# RA2A1 register map
Vendor: Renesas Electronics Corporation; Series: RA2; File version: 1.1
CPU: other r1p0, little endian, MPU, no FPU, VTOR, 2 interrupt priority bits
Registers are 8-bit, read-write, reset 0x0 unless marked. A register's access mark holds for its fields unless they carry their own. Offsets are from the block's base; [hi:lo] are bit positions; {n}, {i} and the like mark numbered series; 'fields as' and 'values as' point back to an identical list.

## USBFS — USB 2.0 FS Module
Base 0x40090000
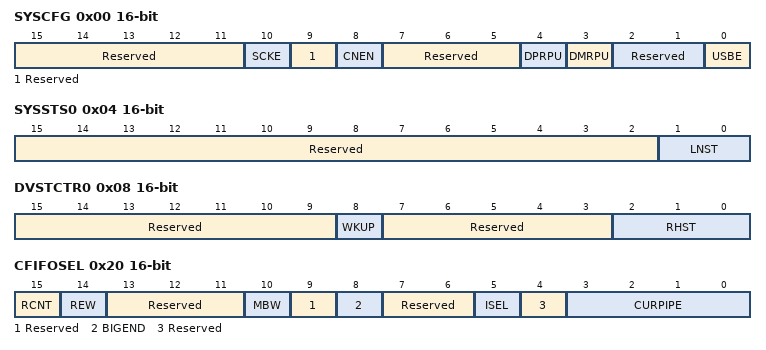
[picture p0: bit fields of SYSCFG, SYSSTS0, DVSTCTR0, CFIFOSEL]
0x00 SYSCFG 16-bit — System Configuration Control Register
  [15:11] Reserved — These bits are read as 00000. The write value should be 00000.
  [10] SCKE — USB Clock Enable
    0=Stops supplying the clock signal to the USB; 1=Enables supplying the clock signal to the USB
  [9] Reserved — This bit is read as 0. The write value should be 0.
  [8] CNEN — CNEN Single End Receiver Enable
    0=Single end receiver operation is disabled; 1=Single end receiver operation is enabled
  [7:5] Reserved — These bits are read as 000. The write value should be 000.
  [4] DPRPU — D+ Line Resistor Control
    0=Pulling up the line is disabled; 1=Pulling up the line is enabled
  [3] DMRPU — D- Line Resistor Control
    values as DPRPU
  [2:1] Reserved — These bits are read as 00. The write value should be 00.
  [0] USBE — USB Operation Enable
    0=USB operation is disabled; 1=USB operation is enabled
0x04 SYSSTS0 16-bit ro — System Configuration Status Register 0
  [15:2] Reserved — These bits are read as 00000000000000.
  [1:0] LNST — USB Data Line Status Monitor
    0=SE0; 1=J-State; 2=K-State; 3=SE1
0x08 DVSTCTR0 16-bit — Device State Control Register 0
  [15:9] Reserved — These bits are read as 0000000. The write value should be 0000000.
  [8] WKUP — Wakeup Detection Enable
    0=Remote wakeup signal is not output; 1=Remote wakeup signal is output
  [7:3] Reserved — These bits are read as 00000. The write value should be 00000.
  [2:0] RHST ro — USB Bus Reset Status
    0=Communication speed not determined; 1=USB bus reset in progress or low-speed connection; 2=USB bus reset in progress or full-speed connection; other=others (Setting prohibited)
0x14 CFIFO 16-bit — CFIFO Port Register
  [15:0] FIFOPORT — FIFO PortRead receive data from the FIFO buffer or write transmit data to the FIFO buffer by accessing these bits.
0x14 CFIFOL (alternate view of CFIFO) — CFIFO Port Register L
0x20 CFIFOSEL 16-bit — CFIFO Port Select Register
  [15] RCNT — Read Count Mode
    0=The DTLN[8:0] bits (CFIFOCRT.DTLN[8:0], D0FIFOCRT.DTLN[8:0], D1FIFOCRT.DTLN[8:0]) are cleared when all of the receive data has been read from the CFIFO.(In double buffer mode, the DTLN[8:0] bit value is cleared when all the data has been read from only a single plane.); 1=The DTLN[8:0] bits are decremented each time the receive data is read from the CFIFO
  [14] REW wo — Buffer Pointer Rewind
    0=The buffer pointer is not rewound; 1=The buffer pointer is rewound
  [13:11] Reserved — These bits are read as 000. The write value should be 000.
  [10] MBW — CFIFO Port Access Bit Width
    0=8-bit width; 1=16-bit width
  [9] Reserved — This bit is read as 0. The write value should be 0.
  [8] BIGEND — CFIFO Port Endian Control
    0=Little endian; 1=Big endian
  [7:6] Reserved — These bits are read as 00. The write value should be 00.
  [5] ISEL — CFIFO Port Access Direction When DCP is Selected
    0=Reading from the buffer memory is selected; 1=Writing to the buffer memory is selected
  [4] Reserved — This bit is read as 0. The write value should be 0.
  [3:0] CURPIPE — CFIFO Port Access Pipe Specification
    0=DCP(Defaultcontrolpipe); {v}=Pipe{v} (v=1..9); other=others (Setting prohibited)
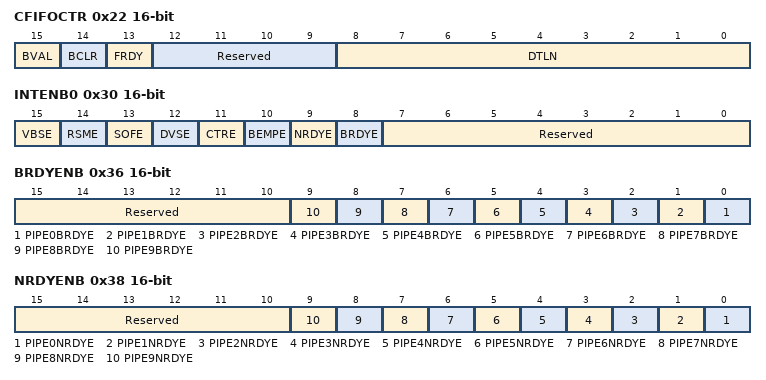
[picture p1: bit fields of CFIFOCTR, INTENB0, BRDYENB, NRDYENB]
0x22 CFIFOCTR 16-bit — CFIFO Port Control Register
  [15] BVAL — Buffer Memory Valid Flag
    0=Invalid; 1=Writing ended
  [14] BCLR wo — CPU Buffer Clear
    0=Invalid; 1=Clears the buffer memory on the CPU side
  [13] FRDY ro — FIFO Port Ready
    0=FIFO port access is disabled; 1=FIFO port access is enabled
  [12:9] Reserved — These bits are read as 0000. The write value should be 0000.
  [8:0] DTLN ro — Receive Data LengthIndicates the length of the receive data.
0x30 INTENB0 16-bit — Interrupt Enable Register 0
  [15] VBSE — VBUS Interrupt Enable
    0=Interrupt output disabled; 1=Interrupt output enabled
  [14] RSME — Resume Interrupt Enable
    0=Interrupt output disabled; 1=Interrupt output enabled
  [13] SOFE — Frame Number Update Interrupt Enable
    0=Interrupt output disabled; 1=Interrupt output enabled
  [12] DVSE — Device State Transition Interrupt Enable
    0=Interrupt output disabled; 1=Interrupt output enabled
  [11] CTRE — Control Transfer Stage Transition Interrupt Enable
    0=Interrupt output disabled; 1=Interrupt output enabled
  [10] BEMPE — Buffer Empty Interrupt Enable
    0=Interrupt output disabled; 1=Interrupt output enabled
  [9] NRDYE — Buffer Not Ready Response Interrupt Enable
    0=Interrupt output disabled; 1=Interrupt output enabled
  [8] BRDYE — Buffer Ready Interrupt Enable
    0=Interrupt output disabled; 1=Interrupt output enabled
  [7:0] Reserved — These bits are read as 00000000. The write value should be 00000000.
0x36 BRDYENB 16-bit — BRDY Interrupt Enable Register
  [15:10] Reserved — These bits are read as 000000. The write value should be 000000.
  [n] PIPE{n}BRDYE (n=0..9) — BRDY Interrupt Enable for PIPE{n}
    0=Interrupt output disabled; 1=Interrupt output enabled
0x38 NRDYENB 16-bit — NRDY Interrupt Enable Register
  [15:10] Reserved — These bits are read as 000000. The write value should be 000000.
  [n] PIPE{n}NRDYE (n=0..9) — NRDY Interrupt Enable for PIPE{n}
    0=Interrupt output disabled; 1=Interrupt output enabled
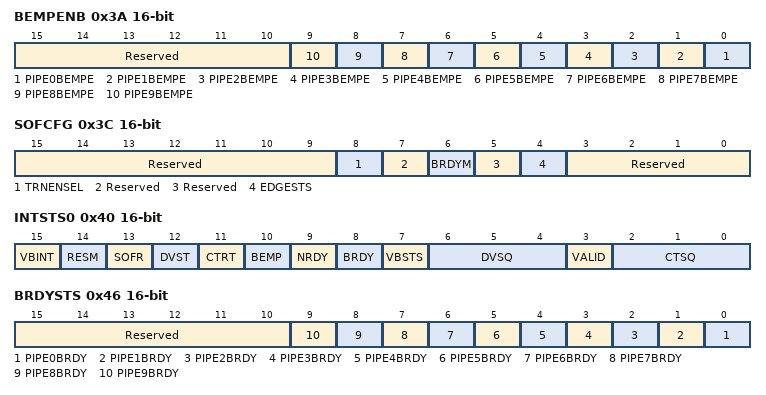
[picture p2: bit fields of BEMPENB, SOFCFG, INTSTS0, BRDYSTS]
0x3A BEMPENB 16-bit — BEMP Interrupt Enable Register
  [15:10] Reserved — These bits are read as 000000. The write value should be 000000.
  [n] PIPE{n}BEMPE (n=0..9) — BEMP Interrupt Enable for PIPE{n}
    0=Interrupt output disabled; 1=Interrupt output enabled
0x3C SOFCFG 16-bit — SOF Output Configuration Register
  [15:9] Reserved — These bits are read as 0000000. The write value should be 0000000.
  [8] TRNENSEL — Transaction-Enabled Time Select
    0=For non-low-speed communication; 1=For low-speed communication
  [7] Reserved — This bit is read as 0. The write value should be 0.
  [6] BRDYM — BRDY Interrupt Status Clear Timing
    0=Software clears the status; 1=The USB clears the status when data has been read from the FIFO buffer or data has been written to the FIFO buffer
  [5] Reserved — This bit is read as 0. The write value should be 0.
  [4] EDGESTS ro — Edge Interrupt Output Status Monitor
    0=before stopping the clock supply to the USB module; 1=the edge interrupt output signal is in the middle of the edge processing
  [3:0] Reserved — These bits are read as 0000. The write value should be 0000.
0x40 INTSTS0 16-bit (reset mask 0xFF7F) — Interrupt Status Register 0
  [15] VBINT write-0-clears read-modifies — VBUS Interrupt Status
    0=VBUS interrupts are not generated; 1=VBUS interrupts are generated
  [14] RESM write-0-clears read-modifies — Resume Interrupt Status
    0=Resume interrupts are not generated; 1=Resume interrupts are generated
  [13] SOFR write-0-clears read-modifies — Frame Number Refresh Interrupt Status
    0=SOF interrupts are not generated; 1=SOF interrupts are generated
  [12] DVST write-0-clears read-modifies — Device State Transition Interrupt Status
    0=Device state transition interrupts are not generated; 1=Device state transition interrupts are generated
  [11] CTRT write-0-clears read-modifies — Control Transfer Stage Transition Interrupt Status
    0=Control transfer stage transition interrupts are not generated; 1=Control transfer stage transition interrupts are generated
  [10] BEMP ro — Buffer Empty Interrupt Status
    0=BEMP interrupts are not generated; 1=BEMP interrupts are generated
  [9] NRDY ro — Buffer Not Ready Interrupt Status
    0=NRDY interrupts are not generated; 1=NRDY interrupts are generated
  [8] BRDY ro — Buffer Ready Interrupt Status
    0=BRDY interrupts are not generated; 1=BRDY interrupts are generated
  [7] VBSTS ro — VBUS Input Status
    0=USB0_VBUS pin is low; 1=USB0_VBUS pin is high
  [6:4] DVSQ ro — Device State
    0=Powered state; 1=Default state; 2=Address state; 3=Configured state; other=others (Suspended state)
  [3] VALID — USB Request Reception
    0=Setup packet is not received; 1=Setup packet is received
  [2:0] CTSQ ro — Control Transfer Stage
    0=Idle or setup stage; 1=Control read data stage; 2=Control read status stage; 3=Control write data stage; 4=Control write status stage; 5=Control write(nodata) status stage; 6=Control transfer sequence error; other=others (Setting prohibited)
0x46 BRDYSTS 16-bit — BRDY Interrupt Status Register
  [15:10] Reserved — These bits are read as 000000. The write value should be 000000.
  [n] PIPE{n}BRDY write-0-clears read-modifies (n=0..9) — BRDY Interrupt Status for PIPE{n}
    0=Interrupts are not generated; 1=Interrupts are generated
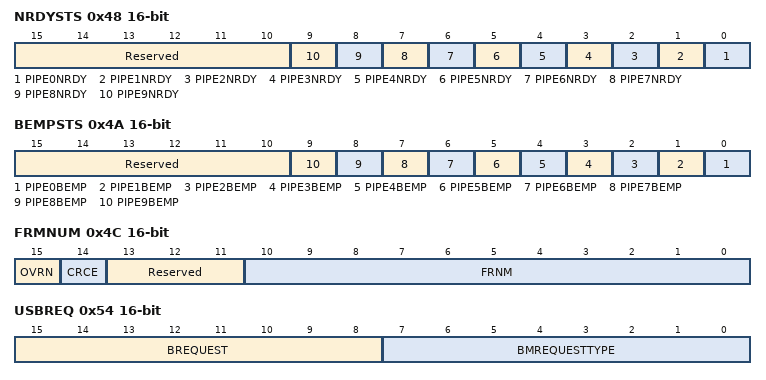
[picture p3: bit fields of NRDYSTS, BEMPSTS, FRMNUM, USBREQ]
0x48 NRDYSTS 16-bit — NRDY Interrupt Status Register
  [15:10] Reserved — These bits are read as 000000. The write value should be 000000.
  [n] PIPE{n}NRDY write-0-clears read-modifies (n=0..9) — NRDY Interrupt Status for PIPE{n}
    0=Interrupts are not generated; 1=Interrupts are generated
0x4A BEMPSTS 16-bit — BEMP Interrupt Status Register
  [15:10] Reserved — These bits are read as 000000. The write value should be 000000.
  [n] PIPE{n}BEMP write-0-clears read-modifies (n=0..9) — BEMP Interrupt Status for PIPE{n}
    0=Interrupts are not generated; 1=Interrupts are generated
0x4C FRMNUM 16-bit — Frame Number Register
  [15] OVRN — Overrun/Underrun Detection Status
    0=No error; 1=An error occurred
  [14] CRCE — Receive Data Error
    0=No error; 1=An error occurred
  [13:11] Reserved — These bits are read as 000. The write value should be 000.
  [10:0] FRNM ro — Frame NumberLatest frame number
0x54 USBREQ 16-bit ro — USB Request Type Register
  [15:8] BREQUEST — RequestThese bits store the USB request bRequest value.
  [7:0] BMREQUESTTYPE — Request TypeThese bits store the USB request bmRequestType value.
0x56 USBVAL 16-bit ro — USB Request Value Register
  [15:0] WVALUE — ValueThese bits store the USB request wValue value.
0x58 USBINDX 16-bit ro — USB Request Index Register
  [15:0] WINDEX — IndexThese bits store the USB request wIndex value.
0x5A USBLENG 16-bit ro — USB Request Length Register
  [15:0] WLENGTUH — LengthThese bits store the USB request wLength value.
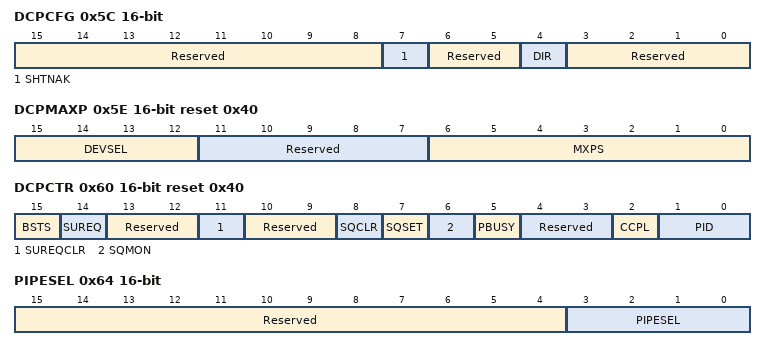
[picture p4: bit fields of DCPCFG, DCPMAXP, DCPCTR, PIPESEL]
0x5C DCPCFG 16-bit — DCP Configuration Register
  [15:8] Reserved — These bits are read as 00000000. The write value should be 00000000.
  [7] SHTNAK — Pipe Disabled at End of Transfer
    0=Pipe continued at the end of transfer; 1=Pipe disabled at the end of transfer
  [6:5] Reserved — These bits are read as 00. The write value should be 00.
  [4] DIR — Transfer Direction
    0=Data receiving direction; 1=Data transmitting direction
  [3:0] Reserved — These bits are read as 0000. The write value should be 0000.
0x5E DCPMAXP 16-bit reset 0x40 — DCP Maximum Packet Size Register
  [15:12] DEVSEL — Device Select
    0=Address 0000; 1=Address 0001; 2=Address 0010; 3=Address 0011; 4=Address 0100; 5=Address 0101; other=others (Settings prohibited.)
  [11:7] Reserved — These bits are read as 00000. The write value should be 00000.
  [6:0] MXPS — Maximum Packet SizeThese bits set the maximum amount of data (maximum packet size) in payloads for the DCP.
    8=8bytes; 16=16bytes; 24=24bytes; 32=32bytes; 40=40bytes; 48=48bytes; 56=56bytes; 64=64bytes; 72=72bytes; 80=80bytes; 88=88bytes; 96=96bytes; 104=104bytes; 112=112bytes; 120=120bytes; other=others (Setting prohibited)
0x60 DCPCTR 16-bit reset 0x40 — DCP Control Register
  [15] BSTS ro — Buffer Status
    0=Buffer access is disabled; 1=Buffer access is enabled
  [14] SUREQ — Setup Token Transmission
    0=Invalid; 1=Transmits the setup packet
  [13:12] Reserved — These bits are read as 00. The write value should be 00.
  [11] SUREQCLR — SUREQ Bit Clear
    0=Invalid; 1=Clears the SUREQ bit to 0
  [10:9] Reserved — These bits are read as 00. The write value should be 00.
  [8] SQCLR wo — Sequence Toggle Bit Clear
    0=Invalid; 1=Specifies DATA0
  [7] SQSET wo — Sequence Toggle Bit Set
    0=Invalid; 1=Specifies DATA1
  [6] SQMON ro — Sequence Toggle Bit Monitor
    0=DATA0; 1=DATA1
  [5] PBUSY ro — Pipe Busy
    0=DCP is not used for the transaction; 1=DCP is used for the transaction
  [4:3] Reserved — These bits are read as 00. The write value should be 00.
  [2] CCPL — Control Transfer End Enable
    0=Invalid; 1=Completion of control transfer is enabled
  [1:0] PID — Response PID
    0=NAK response; 1=BUF response (depending on the buffer state); 2=STALL response; 3=STALL response
0x64 PIPESEL 16-bit — Pipe Window Select Register
  [15:4] Reserved — These bits are read as 000000000000. The write value should be 000000000000.
  [3:0] PIPESEL — Pipe Window Select
    0=No pipe selected; {v}=PIPE{v} (v=4..7); other=others (Settings prohibited.)
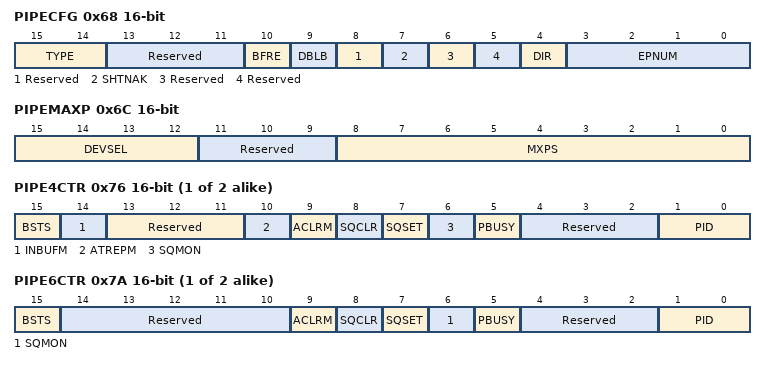
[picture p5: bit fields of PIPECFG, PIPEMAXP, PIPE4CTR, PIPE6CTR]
0x68 PIPECFG 16-bit — Pipe Configuration Register
  [15:14] TYPE — Transfer Type
    0=Pipe not used; 1=Bulk transfer(PIPE1 and PIPE5) /Setting prohibited(PIPE6 to PIPE9); 2=Setting prohibited(PIPE1 and PIPE5) /Interrupt transfer(PIPE6 to PIPE9); 3=Isochronous transfer(PIPE1 and PIPE2) /Setting prohibited(PIPE3 to PIPE9)
  [13:11] Reserved — These bits are read as 000. The write value should be 000.
  [10] BFRE — BRDY Interrupt Operation Specification
    0=BRDY interrupt upon transmitting or receiving data; 1=BRDY interrupt upon completion of reading data
  [9] DBLB — Double Buffer Mode
    0=Single buffer; 1=Double buffer
  [8] Reserved — This bit is read as 0. The write value should be 0.
  [7] SHTNAK — Pipe Disabled at End of Transfer
    0=Pipe assignment continued at the end of transfer; 1=Pipe assignment disabled at the end of transfer
  [6] Reserved — This bit is read as 0. The write value should be 0.
  [5] Reserved — This bit is read as 0. The write value should be 0.
  [4] DIR — Transfer Direction
    0=Receiving direction; 1=Transmitting direction
  [3:0] EPNUM — Endpoint NumberThese bits specify the endpoint number for the selected pipe.Setting 0000b means unused pipe.
0x6C PIPEMAXP 16-bit (reset mask 0xFFBF) — Pipe Maximum Packet Size Register
  [15:12] DEVSEL — Device Select
    values as DCPMAXP.DEVSEL
  [11:9] Reserved — These bits are read as 000. The write value should be 000.
  [8:0] MXPS — Maximum Packet SizePIPE1 and PIPE2: 1 byte (001h) to 256 bytes (100h)PIPE3 to PIPE5: 8 bytes (008h), 16 bytes (010h), 32 bytes (020h), 64 bytes (040h) (Bits [8:7] and [2:0] are not provided.)PIPE6 to PIPE9: 1 byte (001h) to 64 bytes (040h) (Bits [8:7] are not provided.)
{0x6E+2i} PIPE{i}CTR (i=4..5) 16-bit — Pipe {i} Control Register
  [15] BSTS ro — Buffer Status
    0=Buffer access by the CPU is disabled; 1=Buffer access by the CPU is enabled
  [14] INBUFM ro — Transmit Buffer Monitor
    0=No data to be transmitted is in the FIFO buffer; 1=Data to be transmitted is in the FIFO buffer
  [13:11] Reserved — These bits are read as 000. The write value should be 000.
  [10] ATREPM — Auto Response Mode
    0=Auto response is disabled; 1=Auto response is enabled
  [9] ACLRM — Auto Buffer Clear Mode
    0=Disabled; 1=Enabled (all buffers are initialized)
  [8] SQCLR wo — Sequence Toggle Bit Clear
    0=Write disabled; 1=Specifies DATA0
  [7] SQSET wo — Sequence Toggle Bit Set
    0=Write disabled; 1=Specifies DATA1
  [6] SQMON ro — Sequence Toggle Bit Confirmation
    0=DATA0; 1=DATA1
  [5] PBUSY ro — Pipe Busy
    0=The relevant pipe is not used for the transaction; 1=The relevant pipe is used for the transaction
  [4:2] Reserved — These bits are read as 000. The write value should be 000.
  [1:0] PID — Response PID
    values as DCPCTR.PID
{0x6E+2i} PIPE{i}CTR (i=6..7) 16-bit — Pipe {i} Control Register
  [15] BSTS ro — Buffer Status
    0=Buffer access is disabled; 1=Buffer access is enabled
  [14:10] Reserved — These bits are read as 00000. The write value should be 00000.
  [9] ACLRM — Auto Buffer Clear Mode
    0=Auto buffer clear mode is disabled; 1=Auto buffer clear mode is enabled (all buffers are initialized)
  [8] SQCLR wo — Sequence Toggle Bit Clear
    0=Invalid; 1=Specifies DATA0
  [7] SQSET wo — Sequence Toggle Bit Set
    0=Invalid; 1=Specifies DATA1
  [6] SQMON ro — Sequence Toggle Bit Confirmation
    0=DATA0; 1=DATA1
  [5] PBUSY ro — Pipe Busy
    0=The relevant pipe is not used at the USB bus; 1=The relevant pipe is used at the USB bus
  [4:2] Reserved — These bits are read as 000. The write value should be 000.
  [1:0] PID — Response PID
    0=NAK response; 1=BUF response(dependingonthebufferstate); 2=STALL response; 3=STALL response
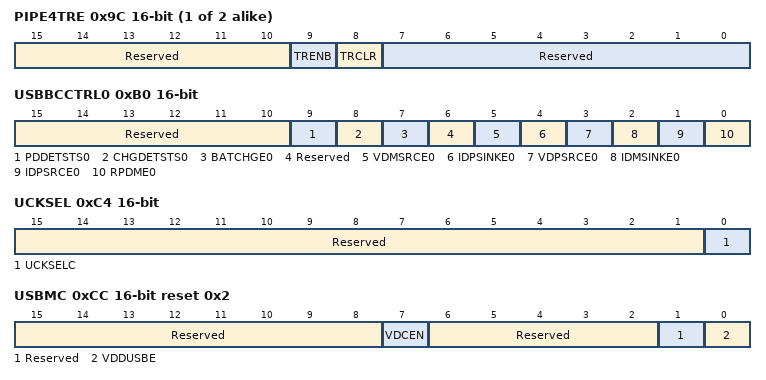
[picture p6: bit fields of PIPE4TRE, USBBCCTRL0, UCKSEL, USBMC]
{0x8C+4i} PIPE{i}TRE (i=4..5) 16-bit — Pipe {i} Transaction Counter Enable Register
  [15:10] Reserved — These bits are read as 000000. The write value should be 000000.
  [9] TRENB — Transaction Counter Enable
    0=Transaction counter is disabled; 1=Transaction counter is enabled
  [8] TRCLR — Transaction Counter Clear
    0=Invalid; 1=The current counter value is cleared
  [7:0] Reserved — These bits are read as 00000000. The write value should be 00000000.
{0x8E+4i} PIPE{i}TRN (i=4..5) 16-bit — Pipe {i} Transaction Counter Register
  [15:0] TRNCNT — Transaction Counter
0xB0 USBBCCTRL0 16-bit — BC Control Register 0
  [15:10] Reserved — These bits are read as 000000. The write value should be 000000.
  [9] PDDETSTS0 ro — D+ Pin 0.6 V Input Detection Status
    0=Not detected; 1=Detected
  [8] CHGDETSTS0 ro — D- Pin 0.6 V Input Detection Status
    0=Not detected; 1=Detected
  [7] BATCHGE0 — BC (Battery Charger) Function General Enable Control
    0=Disabled; 1=Enabled
  [6] Reserved — This bit is read as 0. The write value should be 0.
  [5] VDMSRCE0 — D- Pin VDMSRC (0.6 V) Output Control
    0=Stop; 1=0.6 V output
  [4] IDPSINKE0 — D+ Pin 0.6 V Input Detection (Comparator and Sink) Control
    0=Detection off; 1=Detection on (comparator and sink current on)
  [3] VDPSRCE0 — D+ Pin VDPSRC (0.6 V) Output Control
    0=Stop; 1=0.6 V output
  [2] IDMSINKE0 — D- Pin 0.6 V Input Detection (Comparator and Sink) Control
    values as IDPSINKE0
  [1] IDPSRCE0 — D+ Pin IDPSRC Output Control
    0=Stop; 1=10 uA output
  [0] RPDME0 — D- Pin Pull-Down Control
    0=Pull-down off; 1=Pull-down on
0xC4 UCKSEL 16-bit — USB Clock Selection Register
  [15:1] Reserved — These bits are read as 000000000000000. The write value should be 000000000000000.
  [0] UCKSELC — USB Clock Selection
    0=High-speed on-chip oscillator clock (HOCO) is not selected as USB clock; 1=High-speed on-chip oscillator clock (HOCO) is selected as USB clock
0xCC USBMC 16-bit reset 0x2 — USB Module Control Register
  [15:8] Reserved — These bits are read as 00000000. The write value should be 00000000.
  [7] VDCEN — USB Regulator On/Off Control
    0=USB regulator off; 1=USB regulator on
  [6:2] Reserved — These bits are read as 00000. The write value should be 00000.
  [1] Reserved — This bit is read as 1. The write value should be 1.
  [0] VDDUSBE — USB Reference Power Supply Circuit On/Off Control
    0=USB reference power supply circuit off; 1=USB reference power supply circuit on
